# STM32L4x2_v1r1 register map
File version: 1.0
CPU: CM4 r0p1, little endian, MPU, FPU, 4 interrupt priority bits
Registers are 32-bit, read-write, reset 0x0 unless marked. A register's access mark holds for its fields unless they carry their own. Offsets are from the block's base; [hi:lo] are bit positions; {n}, {i} and the like mark numbered series.

## SWPMI1 — Single Wire Protocol Master Interface
Base 0x40008800
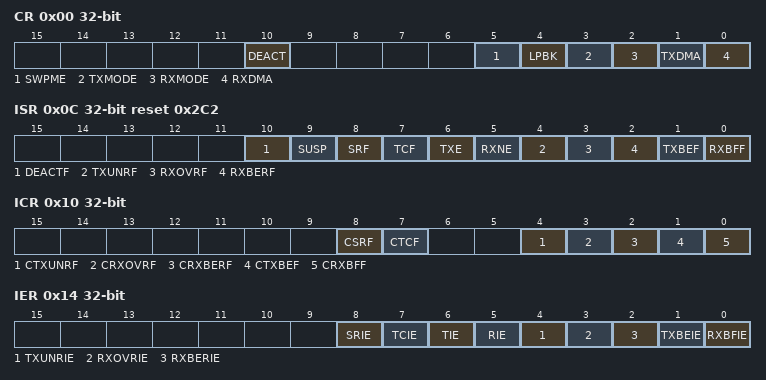
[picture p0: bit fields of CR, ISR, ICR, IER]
0x00 CR — SWPMI Configuration/Control register
  [10] DEACT — Single wire protocol master interface deactivate
  [5] SWPME — Single wire protocol master interface enable
  [4] LPBK — Loopback mode enable
  [3] TXMODE — Transmission buffering mode
  [2] RXMODE — Reception buffering mode
  [1] TXDMA — Transmission DMA enable
  [0] RXDMA — Reception DMA enable
0x04 BRR reset 0x1 — SWPMI Bitrate register
  [5:0] BR — Bitrate prescaler
0x0C ISR ro reset 0x2C2 — SWPMI Interrupt and Status register
  [10] DEACTF — DEACTIVATED flag
  [9] SUSP — SUSPEND flag
  [8] SRF — Slave resume flag
  [7] TCF — Transfer complete flag
  [6] TXE — Transmit data register empty
  [5] RXNE — Receive data register not empty
  [4] TXUNRF — Transmit underrun error flag
  [3] RXOVRF — Receive overrun error flag
  [2] RXBERF — Receive CRC error flag
  [1] TXBEF — Transmit buffer empty flag
  [0] RXBFF — Receive buffer full flag
0x10 ICR wo — SWPMI Interrupt Flag Clear register
  [8] CSRF — Clear slave resume flag
  [7] CTCF — Clear transfer complete flag
  [4] CTXUNRF — Clear transmit underrun error flag
  [3] CRXOVRF — Clear receive overrun error flag
  [2] CRXBERF — Clear receive CRC error flag
  [1] CTXBEF — Clear transmit buffer empty flag
  [0] CRXBFF — Clear receive buffer full flag
0x14 IER — SWPMI Interrupt Enable register
  [8] SRIE — Slave resume interrupt enable
  [7] TCIE — Transmit complete interrupt enable
  [6] TIE — Transmit interrupt enable
  [5] RIE — Receive interrupt enable
  [4] TXUNRIE — Transmit underrun error interrupt enable
  [3] RXOVRIE — Receive overrun error interrupt enable
  [2] RXBERIE — Receive CRC error interrupt enable
  [1] TXBEIE — Transmit buffer empty interrupt enable
  [0] RXBFIE — Receive buffer full interrupt enable
0x18 RFL ro — SWPMI Receive Frame Length register
  [4:0] RFL — Receive frame length
0x1C TDR wo — SWPMI Transmit data register
  [31:0] TD — Transmit data
0x20 RDR ro — SWPMI Receive data register
  [31:0] RD — received data

## NVIC — Nested Vectored Interrupt Controller
Base 0xE000E000
0x04 ICTR ro — Interrupt Controller Type Register
  [3:0] INTLINESNUM — Total number of interrupt lines in groups
{0x100+4i} ISER{i} (i=0..2) — Interrupt Set-Enable Register
  [31:0] SETENA
{0x180+4i} ICER{i} (i=0..2) — Interrupt Clear-Enable Register
  [31:0] CLRENA
{0x200+4i} ISPR{i} (i=0..2) — Interrupt Set-Pending Register
  [31:0] SETPEND
{0x280+4i} ICPR{i} (i=0..2) — Interrupt Clear-Pending Register
  [31:0] CLRPEND
{0x300+4i} IABR{i} ro (i=0..2) — Interrupt Active Bit Register
  [31:0] ACTIVE
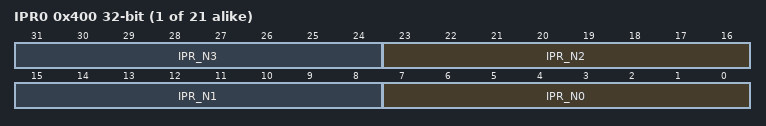
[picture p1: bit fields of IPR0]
{0x400+4i} IPR{i} (i=0..20) — Interrupt Priority Register
  [8n+7:8n] IPR_N{n} (n=0..3)
0xF00 STIR wo — Software Triggered Interrupt Register
  [8:0] INTID — interrupt to be triggered

## CRS — Clock recovery system
Base 0x40006000
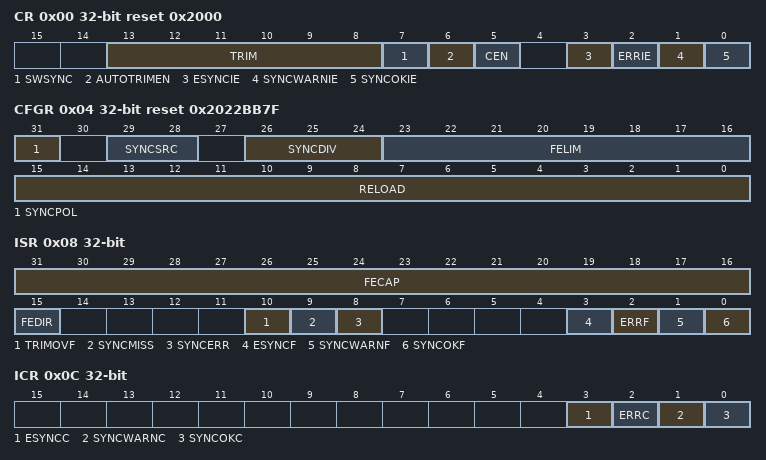
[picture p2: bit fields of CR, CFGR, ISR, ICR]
0x00 CR reset 0x2000 — control register
  [13:8] TRIM — HSI48 oscillator smooth trimming
  [7] SWSYNC — Generate software SYNC event
  [6] AUTOTRIMEN — Automatic trimming enable
  [5] CEN — Frequency error counter enable
  [3] ESYNCIE — Expected SYNC interrupt enable
  [2] ERRIE — Synchronization or trimming error interrupt enable
  [1] SYNCWARNIE — SYNC warning interrupt enable
  [0] SYNCOKIE — SYNC event OK interrupt enable
0x04 CFGR reset 0x2022BB7F — configuration register
  [31] SYNCPOL — SYNC polarity selection
  [29:28] SYNCSRC — SYNC signal source selection
  [26:24] SYNCDIV — SYNC divider
  [23:16] FELIM — Frequency error limit
  [15:0] RELOAD — Counter reload value
0x08 ISR ro — interrupt and status register
  [31:16] FECAP — Frequency error capture
  [15] FEDIR — Frequency error direction
  [10] TRIMOVF — Trimming overflow or underflow
  [9] SYNCMISS — SYNC missed
  [8] SYNCERR — SYNC error
  [3] ESYNCF — Expected SYNC flag
  [2] ERRF — Error flag
  [1] SYNCWARNF — SYNC warning flag
  [0] SYNCOKF — SYNC event OK flag
0x0C ICR — interrupt flag clear register
  [3] ESYNCC — Expected SYNC clear flag
  [2] ERRC — Error clear flag
  [1] SYNCWARNC — SYNC warning clear flag
  [0] SYNCOKC — SYNC event OK clear flag
